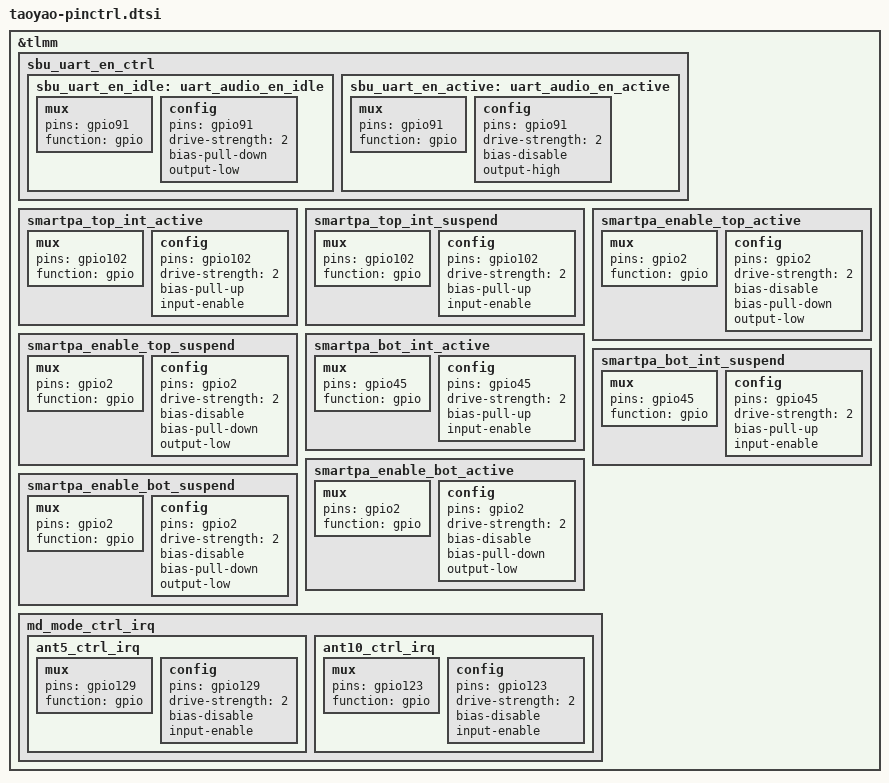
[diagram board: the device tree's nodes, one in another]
/*for taoyao pinctrl */
&tlmm {
sbu_uart_en_ctrl {
		sbu_uart_en_idle: uart_audio_en_idle {
			mux {
				pins = "gpio91";
				function = "gpio";
			};
			config {
				pins = "gpio91";
				drive-strength = <2>;
				bias-pull-down;
				output-low;
			};
		};

		sbu_uart_en_active: uart_audio_en_active {
			mux {
				pins = "gpio91";
				function = "gpio";
			};
			config {
				pins = "gpio91";
				drive-strength = <2>;
				bias-disable;
				output-high;
			};
		};
	};

smartpa_top_int_active: smartpa_top_int_active {
		/* active state */
		mux {
		/* GPIO 113 Interrupt */
			pins = "gpio102";
			function = "gpio";
		};

		config {
			pins = "gpio102";
			drive-strength = <2>; /* 2 MA */
			bias-pull-up;
			input-enable;
		};
	};

	smartpa_top_int_suspend: smartpa_top_int_suspend {
		/* sleep state */
		mux {
		/* GPIO 113 Interrupt */
			pins = "gpio102";
			function = "gpio";
		};

		config {
			pins = "gpio102";
			drive-strength = <2>; /* 2 MA */
			bias-pull-up;
			input-enable;
		};
	};

	smartpa_enable_top_active: smartpa_enable_top_active {
		/* active state */
		mux {
		/* GPIO 114 rst pin */
			pins = "gpio2";
			function = "gpio";
		};

		config {
			pins = "gpio2";
			drive-strength = <2>;
			bias-disable;
			bias-pull-down;
			output-low;
		};
	};

	smartpa_enable_top_suspend: smartpa_enable_top_suspend {
		/* sleep state */
		mux {
			/* GPIO 114 rst pin */
			pins = "gpio2";
			function = "gpio";
		};

		config {
			pins = "gpio2";
			drive-strength = <2>;
			bias-disable;
			bias-pull-down;
			output-low;
		};
	};

	/* speaker switch spk-sw-gpio = <&tlmm 24 0>;
	spk_sw_active: spk_sw_active {
		mux {
			pins = "gpio101";
			function = "gpio";
		};

		config {
			pins = "gpio101";
			drive-strength = <2>;
			bias-disable;
			bias-pull-down;
			output-low;
		};
	};

	spk_sw_inactive: spk_sw_inactive {
		mux {
			pins = "gpio101";
			function = "gpio";
		};

		config {
			pins = "gpio101";
			drive-strength = <2>;
			bias-disable;
			bias-pull-down;
			output-low;
		};
	};*/

	smartpa_bot_int_active: smartpa_bot_int_active {
		/* active state */
		mux {
		/* GPIO 112 Interrupt */
			pins = "gpio45";
			function = "gpio";
		};

		config {
			pins = "gpio45";
			drive-strength = <2>; /* 2 MA */
			bias-pull-up;
			input-enable;
		};
	};

	smartpa_bot_int_suspend: smartpa_bot_int_suspend {
		/* sleep state */
		mux {
		/* GPIO 112 Interrupt */
			pins = "gpio45";
			function = "gpio";
		};

		config {
			pins = "gpio45";
			drive-strength = <2>; /* 2 MA */
			bias-pull-up;
			input-enable;
		};
	};

	smartpa_enable_bot_active: smartpa_enable_bot_active {
		/* active state */
		mux {
		/* GPIO 140 rst pin */
			pins = "gpio2";
			function = "gpio";
		};

		config {
			pins = "gpio2";
			drive-strength = <2>;
			bias-disable;
			bias-pull-down;
			output-low;
		};
	};

	smartpa_enable_bot_suspend: smartpa_enable_bot_suspend {
		/* sleep state */
		mux {
			/* GPIO 140 rst pin */
			pins = "gpio2";
			function = "gpio";
		};

		config {
			pins = "gpio2";
			drive-strength = <2>;
			bias-disable;
			bias-pull-down;
			output-low;
		};
	};
        md_mode_ctrl_irq {
		ant5_ctrl_irq: ant5_ctrl_irq {
			mux {
				pins = "gpio129";
				function = "gpio";
			};

			config {
				pins = "gpio129";
				drive-strength = <2>;
				bias-disable;
				input-enable;
			};
		};

		ant10_ctrl_irq: ant10_ctrl_irq {
			mux {
				pins = "gpio123";
				function = "gpio";
			};

			config {
				pins = "gpio123";
				drive-strength = <2>;
				bias-disable;
				input-enable;
			};
		};
	};
};
